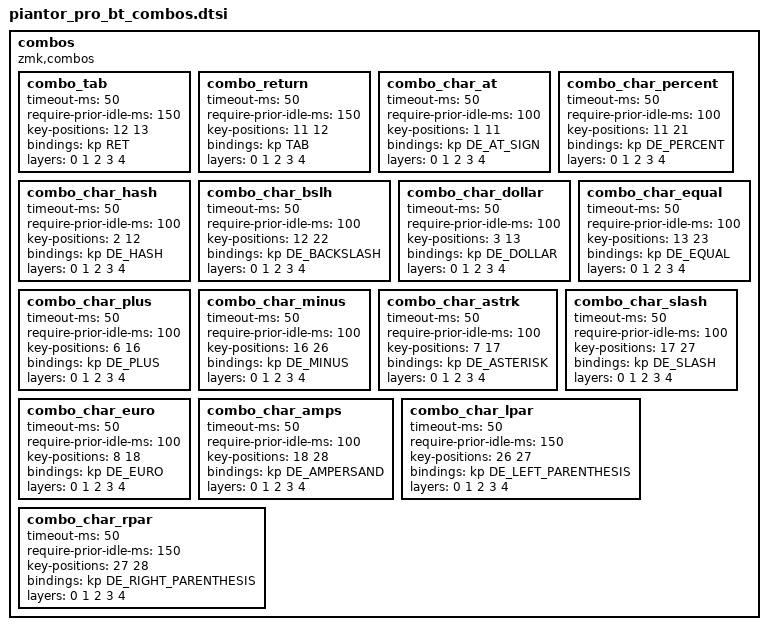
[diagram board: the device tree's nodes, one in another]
combos {
    compatible = "zmk,combos";

    // ===== TAB AND RETURN COMBOS (50ms timeout, 100ms require-prior-idle) =====
    combo_tab {
        timeout-ms = <50>;
        require-prior-idle-ms = <150>;
        key-positions = <12 13>;  // T+S → Return
        bindings = <&kp RET>;
        layers = <0 1 2 3 4>;
    };
    combo_return {
        timeout-ms = <50>;
        require-prior-idle-ms = <150>;
        key-positions = <11 12>;  // R+T → Tab
        bindings = <&kp TAB>;
        layers = <0 1 2 3 4>;
    };

    // ===== VERTICAL COMBOS LEFT CHARACTERS (50ms timeout, 100ms require-prior-idle) =====

    combo_char_at {
        timeout-ms = <50>;
        require-prior-idle-ms = <100>;
        key-positions = <1 11>;  // L+R
        bindings = <&kp DE_AT_SIGN>;
        layers = <0 1 2 3 4>;
    };

    combo_char_percent {
        timeout-ms = <50>;
        require-prior-idle-ms = <100>;
        key-positions = <11 21>;  // R+Q
        bindings = <&kp DE_PERCENT>;
        layers = <0 1 2 3 4>;
    };

    combo_char_hash {
        timeout-ms = <50>;
        require-prior-idle-ms = <100>;
        key-positions = <2 12>;  // D+T
        bindings = <&kp DE_HASH>;
        layers = <0 1 2 3 4>;
    };

    combo_char_bslh {
        timeout-ms = <50>;
        require-prior-idle-ms = <100>;
        key-positions = <12 22>;  // T+M
        bindings = <&kp DE_BACKSLASH>;
        layers = <0 1 2 3 4>;
    };

    combo_char_dollar {
        timeout-ms = <50>;
        require-prior-idle-ms = <100>;
        key-positions = <3 13>;  // C+S
        bindings = <&kp DE_DOLLAR>;
        layers = <0 1 2 3 4>;
    };

    combo_char_equal {
        timeout-ms = <50>;
        require-prior-idle-ms = <100>;
        key-positions = <13 23>;  // S+W
        bindings = <&kp DE_EQUAL>;
        layers = <0 1 2 3 4>;
    };

    // ===== VERTICAL COMBOS RIGHT CHARACTERS (50ms timeout, 100ms require-prior-idle) =====

    combo_char_plus {
        timeout-ms = <50>;
        require-prior-idle-ms = <100>;
        key-positions = <6 16>;  // Z+H
        bindings = <&kp DE_PLUS>;
        layers = <0 1 2 3 4>;
    };

    combo_char_minus {
        timeout-ms = <50>;
        require-prior-idle-ms = <100>;
        key-positions = <16 26>;  // H+F
        bindings = <&kp DE_MINUS>;
        layers = <0 1 2 3 4>;
    };

    combo_char_astrk {
        timeout-ms = <50>;
        require-prior-idle-ms = <100>;
        key-positions = <7 17>;  // Q+A
        bindings = <&kp DE_ASTERISK>;
        layers = <0 1 2 3 4>;
    };

    combo_char_slash {
        timeout-ms = <50>;
        require-prior-idle-ms = <100>;
        key-positions = <17 27>;  // A+,
        bindings = <&kp DE_SLASH>;
        layers = <0 1 2 3 4>;
    };

    combo_char_euro {
        timeout-ms = <50>;
        require-prior-idle-ms = <100>;
        key-positions = <8 18>;  // U+E
        bindings = <&kp DE_EURO>;
        layers = <0 1 2 3 4>;
    };

    combo_char_amps {
        timeout-ms = <50>;
        require-prior-idle-ms = <100>;
        key-positions = <18 28>;  // E+.
        bindings = <&kp DE_AMPERSAND>;
        layers = <0 1 2 3 4>;
    }; 

    // ===== HORIZONTAL COMBOS RIGHT CHARACTERS (50ms timeout, 100ms require-prior-idle) =====

    // ===== HORIZONTAL COMBOS RIGHT CHARACTERS (50ms timeout, 100ms require-prior-idle) =====

    combo_char_lpar {
        timeout-ms = <50>;
        require-prior-idle-ms = <150>;
        key-positions = <26 27>;  // F+,
        bindings = <&kp DE_LEFT_PARENTHESIS>;
        layers = <0 1 2 3 4>;
    };

    combo_char_rpar {
        timeout-ms = <50>;
        require-prior-idle-ms = <150>;
        key-positions = <27 28>;  // ,+.
        bindings = <&kp DE_RIGHT_PARENTHESIS>;
        layers = <0 1 2 3 4>;
    }; 

};
